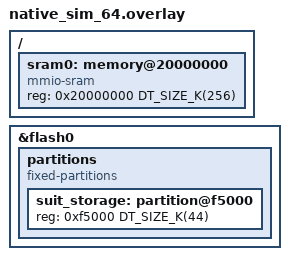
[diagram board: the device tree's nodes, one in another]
/*
 * Copyright (c) 2022 Nordic Semiconductor ASA
 *
 * SPDX-License-Identifier: LicenseRef-Nordic-5-Clause
 */

&flash0 {
	partitions {
		compatible = "fixed-partitions";
		#address-cells = <1>;
		#size-cells = <1>;

		/* Use the last 44KB of NVM as suit storage. */
		suit_storage: partition@f5000 {
			reg = <0xf5000 DT_SIZE_K(44)>;
		};
	};
};

/ {
	sram0: memory@20000000 {
		compatible = "mmio-sram";
		reg = <0x20000000 DT_SIZE_K(256)>;
	};
};
